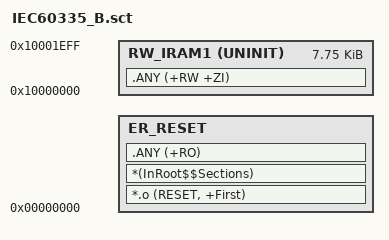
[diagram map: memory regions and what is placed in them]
; *************************************************************
; *** Scatter-Loading Description File generated by uVision ***
; *************************************************************

LR_IROM1 0x0 0x00007FF0  {    ; load region size_region

	ER_RESET +0 {
		*.o (RESET, +First)
		*(InRoot$$Sections)
		.ANY (+RO)
	}

  	RW_IRAM1 0x10000000 UNINIT 0x00001F00  {  ; RW data
		.ANY (+RW +ZI)
	}

}

;LR_IROM2 0x00007FF0 0x10 {

;	ER_LASTSECTION +0 {
;		*(.IEC60335_B_lastFashSection)
;	}	
;}
